# DSI_PHY register map
Vendor: Texas Instruments
Peripheral module from a debugger description file (folder omap34xx).
Registers are 32-bit, read-write, reset 0x625D21A0 unless marked. A register's access mark holds for its fields unless they carry their own. Offsets are as the file gives them; lines under a group give offsets from that group; [hi:lo] are bit positions; {n}, {i} and the like mark numbered series; 'fields as' and 'values as' point back to an identical list; <NAME> marks a mode.

## DSI_PHY
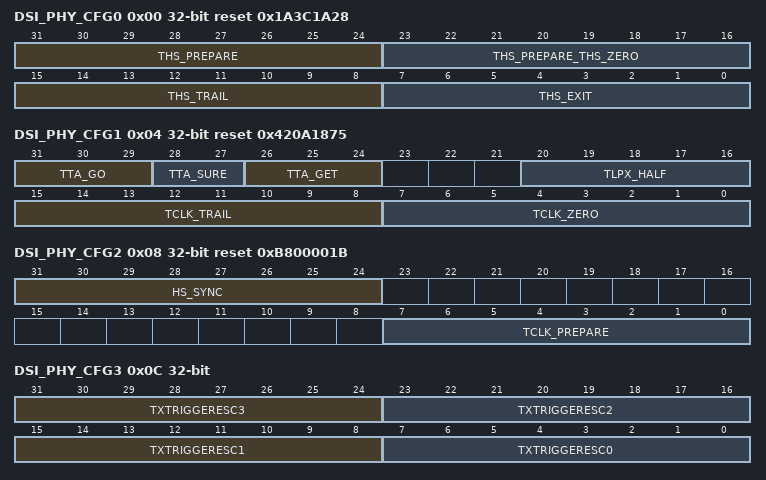
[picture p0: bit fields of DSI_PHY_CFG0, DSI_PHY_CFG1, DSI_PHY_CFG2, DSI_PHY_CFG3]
0x00 DSI_PHY_CFG0 reset 0x1A3C1A28 — Configuration register for HS mode timings
  [31:24] THS_PREPARE — THS-PREPARE timing parameter in multiples of DDR clock period. DDR clock = CLKIN4DDR/4.Programmed value = CEIL(70 ns/DDR clock period) + 2
  [23:16] THS_PREPARE_THS_ZERO — THS-PREPARE + THS-ZERO timing parameter in multiples of DDR clock period. DDR clock = CLKIN4DDR/4.Programmed value = ceil(175 ns/DDR clock period) + 2
  [15:8] THS_TRAIL — THS-TRAIL timing parameter in multiples of DDR clock period. DDR clock = CLKIN4DDR/4. Programmed value = ceil(60 ns/DDR clock period) + 5
  [7:0] THS_EXIT — Ths-exit timing parameter in multiples of DDR clock period. DDR clock = CLKIN4DDR/4).Programmed value = ceil(145 ns/DDR clock period).
0x04 DSI_PHY_CFG1 reset 0x420A1875 — Configuration register for LP mode and HS mode timings
  [31:29] TTA_GO — TTA-GO timing in terms of number of TXCLKESC clocksDefault value: 4 cycles .
    {v}={v+2} cycles (v=0..7)
  [28:27] TTA_SURE — TTA-SURE timing in terms of number of TXCLKESC clocksDefault value: 2 cycles .
    0=2 cycles; 1=1 cycle; 2=3 cycles; 3=4 cycles
  [26:24] TTA_GET — TTA-GET timing in terms of number of TXCLKESC clocksDefault value: 5 cycles .
    {v}={v+3} cycles (v=0..7)
  [20:16] TLPX_HALF — (TLPX)/2 timing parameter in multiples of DDR clock frequency. DDR clock = CLKIN4DDR/4. Programmed value = ceil(25ns/DDR clock period)Default value : 10 (for 400 MHz)Note: TLPX is used to define the length of LP-01 state in HS Start of Transmission sequences on clock and data lanes. For all other purposes TLPX is defined by the period of TxLPEsc clock.
  [15:8] TCLK_TRAIL — TCLK-TRAIL timing parameter in multiples of DDR clock frequency. DDR clock = CLKIN4DDR/4. Programmed value = ceil(60 ns/DDR clock period) + 2
  [7:0] TCLK_ZERO — TCLK-ZERO timing parameter in multiples of DDR clock period. DDR clock = CLKIN4DDR/4. Programmed value = ceil(260 ns/DDR clock period)
0x08 DSI_PHY_CFG2 reset 0xB800001B — Sync pattern and reserved bits
  [31:24] HS_SYNC — HS sync pattern.Default = 184 (0xB8)
  [7:0] TCLK_PREPARE — TCLK-PREPARE timing parameter in multiples of DDR clock period.DDR clock = CLKIN4DDR/4. Programmed value = ceil(65 ns/DDR clock period)
0x0C DSI_PHY_CFG3 — TX trigger patterns
  [31:24] TXTRIGGERESC3 — Transmitted pattern when TXTRIGGERESC3 is asserted (first bit transmitted to last bit transmitted)Default: 01100010 .
  [23:16] TXTRIGGERESC2 — Default: 01011101
  [15:8] TXTRIGGERESC1 — Default: 00100001
  [7:0] TXTRIGGERESC0 — Default: 10100000
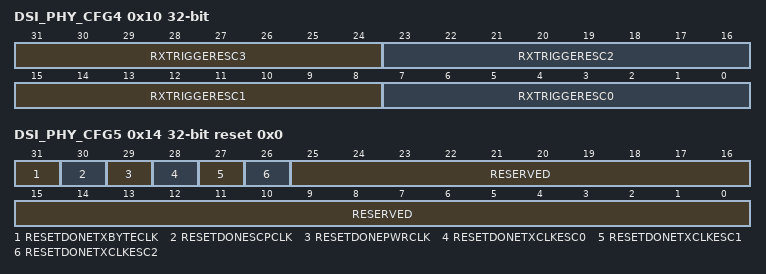
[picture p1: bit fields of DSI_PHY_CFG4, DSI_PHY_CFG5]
0x10 DSI_PHY_CFG4 — RX trigger patterns
  [31:24] RXTRIGGERESC3 — Received pattern for which RXTRIGGERESC3 is asserted (first bit transmitted to last bit transmitted)Default: 01100010 .
  [23:16] RXTRIGGERESC2 — Default: 01011101
  [15:8] RXTRIGGERESC1 — Default: 00100001
  [7:0] RXTRIGGERESC0 — Default: 10100000
0x14 DSI_PHY_CFG5 ro reset 0x0 — Reset done bits
  [31] RESETDONETXBYTECLK
    0=No reset; 1=Reset done for the TXBYTECLK domain
  [30] RESETDONESCPCLK
    0=No reset; 1=Reset done for the SCP clock domain
  [29] RESETDONEPWRCLK
    0=No reset; 1=Reset done for the PWR clock domain
  [28] RESETDONETXCLKESC0
    0=No reset; 1=Reset done for the TXCLKESC domain for lane 0
  [27] RESETDONETXCLKESC1
    0=No reset; 1=Reset done for the TXCLKESC domain for lane 1
  [26] RESETDONETXCLKESC2
    0=No reset; 1=Reset done for the TXCLKESC domain for lane 2
  [25:0] RESERVED — Read-Only register. Read returns zero
